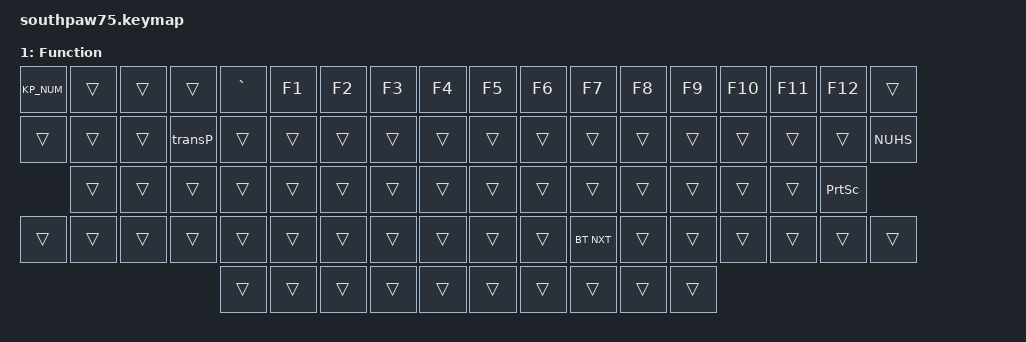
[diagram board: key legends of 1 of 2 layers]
#include <behaviors.dtsi>
#include <dt-bindings/zmk/keys.h>
#include <dt-bindings/zmk/bt.h>
#include <dt-bindings/zmk/outputs.h>

/ {
	keymap {
		compatible = "zmk,keymap";

		default_layer {
			label = "Default";
// ----------------------------------------------------------------------------------------------------------------------------------------------------------------------------------------------
// |   ESC   |    /    |    *    |    -    |   GRAVE |    1    |    2    |    3    |    4    |    5    |    6    |    7    |    8    |    9    |    0    |    -    |    =    |      BKSPACE     |
// |    7    |    8    |    9    |    +    |   TAB      |    Q    |    W    |    E    |    R    |    T    |    Y    |    U    |    I    |    O    |    P    |    [    |    ]    |   NON_US_HASH |
// |    4    |    5    |    6    |         |   CAPSLOCK    |    A    |    S    |    D    |    F    |    G    |    H    |    J    |    K    |    L    |    ;    |    '    |     ANSI ENTER       |
// |    1    |    2    |    3    | RETURN  |   SHIFT  |  NUBS  |    Z    |    X    |    C    |    V    |    B    |    N    |    M    |    ,    |    .    |    /    |            SHIFT           |
// |         0         |    .    |         |   CTRL   |    WIN   |    ALT   |                              SPACE                             |    ALT    |    DEL     |    FN     |    CTRL     |
// ----------------------------------------------------------------------------------------------------------------------------------------------------------------------------------------------

			bindings = <
			&kp ESC      &kp KP_SLASH    &kp KP_ASTERISK  &kp KP_MINUS	&kp GRAVE 	&kp N1    		&kp N2		&kp N3 	&kp N4	&kp N5 	&kp N6 	&kp N7	&kp N8 	&kp N9    	&kp N0    	&kp MINUS	&kp EQUAL    		&kp BSPC
			&kp KP_N7    &kp KP_N8       &kp KP_N9        &kp KP_PLUS   &kp TAB		&kp Q     		&kp W     	&kp E 	&kp R 	&kp T	&kp Y  	&kp U  	&kp I	&kp O     	&kp P      	&kp LBKT	&kp RBKT    		&kp NON_US_HASH
			&kp KP_N4    &kp KP_N5       &kp KP_N6                      &kp CLCK 	&kp A     		&kp S     	&kp D 	&kp F 	&kp G	&kp H  	&kp J 	&kp K	&kp L     	&kp SEMI	&kp APOS	&kp RETURN
			&kp KP_N1    &kp KP_N2       &kp KP_N3        &kp KP_ENTER  &kp LSHFT  	&kp NON_US_BSLH	&kp Z		&kp X  	&kp C  	&kp V	&kp B  	&kp N	&kp M 	&kp COMMA	&kp DOT   	&kp FSLH   	&kp RSHFT			
			&kp KP_N0                    &kp KP_DOT                     &kp LCTRL 	&kp LGUI  		&kp LALT							&kp SPACE 							&kp RALT  	&kp DEL  	&mo 1  			&kp RCTRL
			>;
		};



		function_layer {
			label = "Function";
// ----------------------------------------------------------------------------------------------------------------------------------------------------------------------------------------------
// |  NLOCK  |         |         |         |    |    F1   |    F2   |    F3   |    F4   |    F5   |    F6   |    F7   |    F8   |    F9   |   F10   |   F11   |   F12   |                       |
// |         |         |         |         |            |         |         |         |         |         |         |         |         |         |         |         |         |       NUHS    |
// |         |         |         |         |                |         |         |         |         |         |         |         |         |         |         |         |          |  PSCRN 	|
// |         |         |         |         |            |       |         |         |         |         |         |         |         |         |         |         |              	|       |
// |                   |         |         |            |          |           |                                                              |           |           |           |             |
// ----------------------------------------------------------------------------------------------------------------------------------------------------------------------------------------------

			bindings = <
			&KP_NUM        	&trans     		&trans  		&trans   	&kp GRAVE  &kp F1    &kp F2    &kp F3     &kp F4    &kp F5 	&kp F6  	&kp F7  	&kp F8 	&kp F9  		&kp F10    	&kp F11	&kp F12	&trans
			&trans  	&trans 	&trans  	&transP   	&trans     &trans    &trans    &trans     &trans    &trans 	&trans 		&trans  	&trans  	&trans    	&trans	&trans 	&trans	&kp NUHS
			&trans 		&trans	&trans                  	&trans     &trans    &trans    &trans     &trans    &trans 	&trans	&trans 	&trans   	&trans	&trans     	&trans	&kp PSCRN
			&trans	&trans	&trans	&trans       	&trans     &trans    &trans    &trans     &trans    &trans 	&trans   	&bt BT_NXT	&trans  	&trans    	&trans     	&trans	&trans	&trans
			&trans               		&trans                          &trans     &trans    &trans    								&trans     										&trans    	&trans 	&trans 	&trans
			>;
		};
	};
};
